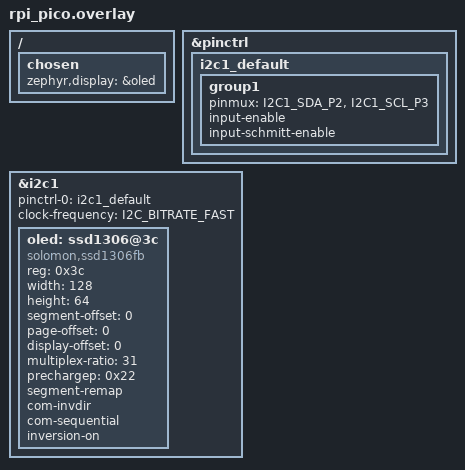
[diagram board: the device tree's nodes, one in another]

/**
 * Generated by Shield Wizard for ZMK
 * Applies to shield "travis_erg2026" with board "rpi_pico" only
 */

#include <dt-bindings/pinctrl/rpi-pico-rp2040-pinctrl.h>

//
// ======== i2c1 ========
//

// pin control for i2c1
// SDA on GP2
// SCL on GP3
&pinctrl {
    i2c1_default: i2c1_default {
        group1 {
            pinmux = <I2C1_SDA_P2>, <I2C1_SCL_P3>;
            input-enable;
            input-schmitt-enable;
        };
    };
};
&i2c1 {
    status = "okay";
    pinctrl-0 = <&i2c1_default>;
    pinctrl-names = "default";
    clock-frequency = <I2C_BITRATE_FAST>;
};

// devices on i2c1

&i2c1 {
    oled: ssd1306@3c {
        compatible = "solomon,ssd1306fb";
        reg = <0x3c>;
        width = <128>;
        height = <64>;

        segment-offset = <0>;
        page-offset = <0>;
        display-offset = <0>;
        multiplex-ratio = <31>;
        prechargep = <0x22>;
        segment-remap;
        com-invdir;
        com-sequential;
        inversion-on;
    };
};
/ {
    chosen {
        zephyr,display = &oled;
    };
};
